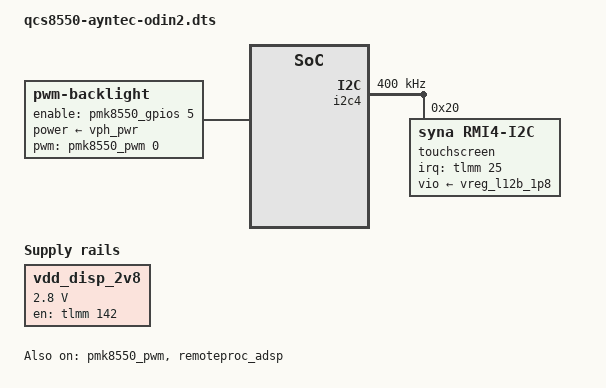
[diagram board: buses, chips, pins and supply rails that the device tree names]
// SPDX-License-Identifier: BSD-3-Clause
/*
 * Copyright (c) 2025, Teguh Sobirin.
 */

/dts-v1/;

#include <dt-bindings/gpio/gpio.h>
#include <dt-bindings/interrupt-controller/irq.h>
#include "qcs8550-ayntec-common.dtsi"

&{/} {
	model = "AYN Odin 2";
	compatible = "ayntec,odin2", "qcom,qcs8550", "qcom,sm8550";

	backlight: backlight {
		compatible = "pwm-backlight";
		pwms = <&pmk8550_pwm 0 860000>;
		brightness-levels = <1023 0>;
		num-interpolated-steps = <1023>;
		default-brightness-level = <600>;
		power-supply = <&vph_pwr>;
		enable-gpios = <&pmk8550_gpios 5 GPIO_ACTIVE_HIGH>;
		pinctrl-0 = <&pwm_backlight_default>;
		pinctrl-names = "default";

		status = "okay";
	};

	vdd_disp_2v8: vdd-disp-2v8-regulator {
		compatible = "regulator-fixed";
		regulator-name = "vdd_disp_2v8";

		regulator-min-microvolt = <2800000>;
		regulator-max-microvolt = <2800000>;

		gpio = <&tlmm 142 GPIO_ACTIVE_HIGH>;
		enable-active-high;
	};
};

&i2c4 {
	clock-frequency = <400000>;

	status = "okay";

	#address-cells = <1>;
	#size-cells = <0>;

	touchscreen@20 {
		compatible = "syna,rmi4-i2c";
		reg = <0x20>;
		#address-cells = <1>;
		#size-cells = <0>;
		interrupt-parent = <&tlmm>;
		interrupts = <25 IRQ_TYPE_EDGE_FALLING>;

		pinctrl-names = "default", "sleep";
		pinctrl-0 = <&ts_p_int_default>;
		pinctrl-1 = <&ts_p_int_sleep>;

		vio-supply = <&vreg_l12b_1p8>;

		syna,startup-delay-ms = <200>;
		syna,reset-delay-ms = <200>;

		rmi4-f01@1 {
			syna,nosleep-mode = <0x1>;
			reg = <0x1>;
		};

		rmi4-f12@12 {
			reg = <0x12>;
			syna,rezero-wait-ms = <20>;
			syna,clip-x-low = <0>;
			syna,clip-y-low = <0>;
			syna,clip-x-high = <1080>;
			syna,clip-y-high = <1920>;
			syna,sensor-type = <1>;
			touchscreen-swapped-x-y;
		};
	};
};

/* There is an hdmi bridge on i2c_hub_0@48, but it is not currently supported */

&pmk8550_pwm {
	status = "okay";
};

&remoteproc_adsp {
	firmware-name = "qcom/sm8550/ayntec/odin2/adsp.mbn",
			"qcom/sm8550/ayntec/odin2/adsp_dtb.mbn";

	status = "okay";
};

&spk_amp_l {
	firmware-name = "qcom/sm8550/ayntec/odin2/aw883xx_acf.bin";
};

&spk_amp_r {
	firmware-name = "qcom/sm8550/ayntec/odin2/aw883xx_acf.bin";
};

